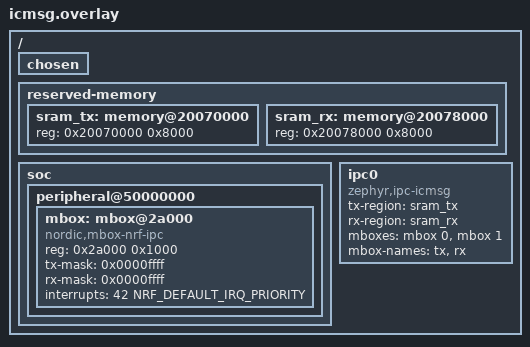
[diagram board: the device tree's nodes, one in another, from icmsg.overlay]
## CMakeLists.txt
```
#
# Copyright (c) 2024 Nordic Semiconductor ASA
#
# SPDX-License-Identifier: LicenseRef-Nordic-5-Clause
#

cmake_minimum_required(VERSION 3.20.0)

find_package(Zephyr REQUIRED HINTS $ENV{ZEPHYR_BASE})
project(ipc_service_host)

target_sources(app PRIVATE src/main.c)
if(CONFIG_SOC_NRF54H20_IRON)
  target_sources(app PRIVATE periphconf_migrated_src/periphconf_migrated_from_uicr.c)
endif()
```

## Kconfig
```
#
# Copyright (c) 2022 Nordic Semiconductor ASA
#
# SPDX-License-Identifier: LicenseRef-Nordic-5-Clause
#

source "Kconfig.zephyr"
rsource "Kconfig.common"
```

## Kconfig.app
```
#
# Copyright (c) 2022 Nordic Semiconductor ASA
#
# SPDX-License-Identifier: LicenseRef-Nordic-5-Clause
#

config APP_IPC_SERVICE_SEND_INTERVAL
	int "Ipc service sending interval [us]"
	default 30 if BOARD_NRF5340DK_NRF5340_CPUNET
	default 70
	help
	  Time in micro seconds between sending subsequent data packages over
	  IPC service. Since kernel timeout has 1 ms resolution, the value is
	  rounded down. If value of this option is lower than 1000 us, busy
	  wait is used instead of sleep.

config APP_IPC_SERVICE_MESSAGE_LEN
	int "Length of single IPC message in bytes"
	default 100
```

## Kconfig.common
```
#
# Copyright (c) 2024 Nordic Semiconductor ASA
#
# SPDX-License-Identifier: LicenseRef-Nordic-5-Clause
#

config APP_IPC_SERVICE_SEND_INTERVAL
	int "Ipc service sending interval [us]"
	default 30 if BOARD_NRF5340DK_NRF5340_CPUNET || BOARD_NRF7002DK_NRF5340_CPUNET
	default 70
	help
	  Time in micro seconds between sending subsequent data packages over
	  IPC service. Since kernel timeout has 1 ms resolution, the value is
	  rounded down. If value of this option is lower than 1000 us, busy
	  wait is used instead of sleep.

config APP_IPC_SERVICE_MESSAGE_LEN
	int "Length of single IPC message in bytes"
	default 100
```

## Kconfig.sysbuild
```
#
# Copyright (c) 2024 Nordic Semiconductor ASA
#
# SPDX-License-Identifier: LicenseRef-Nordic-5-Clause
#

if SUPPORT_PPRCORE

choice PPRCORE
	default PPRCORE_REMOTE if SOC_SERIES_NRF92
	default PPRCORE_NONE

config PPRCORE_REMOTE
	bool "remote image"

endchoice

config PPRCORE_IMAGE_NAME
	default "remote" if PPRCORE_REMOTE

config PPRCORE_IMAGE_PATH
	default "$(APP_DIR)/remote" if PPRCORE_REMOTE

endif # SUPPORT_PPRCORE

if SUPPORT_NETCORE

choice NETCORE
	default NETCORE_REMOTE

config NETCORE_REMOTE
	bool "remote image"

endchoice

config NETCORE_IMAGE_NAME
	default "remote" if NETCORE_REMOTE

config NETCORE_IMAGE_PATH
	default "$(APP_DIR)/remote" if NETCORE_REMOTE

endif # SUPPORT_NETCORE

if SUPPORT_FLPRCORE && !SOC_SERIES_NRF92 && !SUPPORT_PPRCORE

choice FLPRCORE
	default FLPRCORE_REMOTE

config FLPRCORE_REMOTE
	bool "remote image"

endchoice

config FLPRCORE_IMAGE_NAME
	default "remote" if FLPRCORE_REMOTE

config FLPRCORE_IMAGE_PATH
	default "$(APP_DIR)/remote" if FLPRCORE_REMOTE

endif # SUPPORT_FLPRCORE && !SOC_SERIES_NRF92 && !SUPPORT_PPRCORE

source "share/sysbuild/Kconfig"
```

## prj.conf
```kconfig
# Copyright (c) 2024 Nordic Semiconductor ASA
# SPDX-License-Identifier: LicenseRef-Nordic-5-Clause

CONFIG_PRINTK=y

CONFIG_LOG=y
CONFIG_LOG_PROCESS_THREAD_PRIORITY=-15
CONFIG_LOG_PROCESS_THREAD_CUSTOM_PRIORITY=y

CONFIG_HEAP_MEM_POOL_SIZE=4096

CONFIG_MBOX=y

CONFIG_IPC_SERVICE=y
CONFIG_IPC_SERVICE_LOG_LEVEL_INF=y
```

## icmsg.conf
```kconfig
CONFIG_APP_IPC_SERVICE_SEND_INTERVAL=60
```

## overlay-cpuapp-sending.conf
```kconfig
# Simulate sending from App core only, by decreasing
# App core sending interval to relatively low value.
CONFIG_APP_IPC_SERVICE_SEND_INTERVAL=1
```

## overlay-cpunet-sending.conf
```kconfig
# Simulate sending from Net core only, by increasing
# App core sending interval to relatively high value.
CONFIG_APP_IPC_SERVICE_SEND_INTERVAL=20000000
```

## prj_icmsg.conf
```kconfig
CONFIG_IPC_SERVICE=y

CONFIG_PRINTK=y
CONFIG_LOG=y

CONFIG_APP_IPC_SERVICE_SEND_INTERVAL=60

CONFIG_HEAP_MEM_POOL_SIZE=4096

CONFIG_IPC_SERVICE_LOG_LEVEL_INF=y
CONFIG_IPC_SERVICE_BACKEND_ICMSG=y
CONFIG_MBOX=y

CONFIG_LOG_PROCESS_THREAD_PRIORITY=-15
CONFIG_LOG_PROCESS_THREAD_CUSTOM_PRIORITY=y
```

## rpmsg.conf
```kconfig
CONFIG_OPENAMP=y
CONFIG_OPENAMP_SLAVE=n
```

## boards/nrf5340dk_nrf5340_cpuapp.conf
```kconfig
#
# Copyright (c) 2022 Nordic Semiconductor ASA
#
# SPDX-License-Identifier: LicenseRef-Nordic-5-Clause
#

CONFIG_BOARD_ENABLE_CPUNET=y
CONFIG_OPENAMP=y
CONFIG_OPENAMP_SLAVE=n
```

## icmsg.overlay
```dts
/*
* Copyright (c) 2022 Nordic Semiconductor ASA
*
* SPDX-License-Identifier: Apache-2.0
*/

/delete-node/ &ipc0;

/ {
	chosen {
		/delete-property/ zephyr,ipc_shm;
	};

	reserved-memory {
		/delete-node/ memory@20070000;

		sram_tx: memory@20070000 {
			reg = <0x20070000 0x8000>;
		};

		sram_rx: memory@20078000 {
			reg = <0x20078000 0x8000>;
		};
	};

	soc {
		peripheral@50000000 {
			/delete-node/ ipc@2a000;

			mbox: mbox@2a000 {
				compatible = "nordic,mbox-nrf-ipc";
				reg = <0x2a000 0x1000>;
				tx-mask = <0x0000ffff>;
				rx-mask = <0x0000ffff>;
				interrupts = <42 NRF_DEFAULT_IRQ_PRIORITY>;
				#mbox-cells = <1>;
				status = "okay";
			};
		};
	};

	ipc0: ipc0 {
		compatible = "zephyr,ipc-icmsg";
		tx-region = <&sram_tx>;
		rx-region = <&sram_rx>;
		mboxes = <&mbox 0>, <&mbox 1>;
		mbox-names = "tx", "rx";
		status = "okay";
	};
};
```

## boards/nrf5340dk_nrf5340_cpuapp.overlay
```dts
/*
 * Copyright (c) 2026 Nordic Semiconductor ASA
 *
 * SPDX-License-Identifier: Apache-2.0
 */

#include <zephyr/dt-bindings/ipc_service/static_vrings.h>

/delete-node/ &ipc0;

/ {
	chosen {
		/delete-property/ zephyr,ipc_shm;
		/delete-property/ zephyr,bt-hci;
	};
};

/ {
	reserved-memory {
		#address-cells = <1>;
		#size-cells = <1>;

		sram_ipc0: memory@20070000 {
			reg = <0x20070000 DT_SIZE_K(64)>;
		};
	};

	ipc0: ipc0 {
		compatible = "zephyr,ipc-openamp-static-vrings";
		memory-region = <&sram_ipc0>;
		mboxes = <&mbox 0>, <&mbox 1>;
		mbox-names = "tx", "rx";
		role = "host";
		zephyr,buffer-size = <128>;
		status = "okay";
	};
};
```

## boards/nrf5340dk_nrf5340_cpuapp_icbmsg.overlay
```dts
/*
 * Copyright (c) 2025 Nordic Semiconductor ASA
 *
 * SPDX-License-Identifier: LicenseRef-Nordic-5-Clause
 */

/delete-node/ &ipc0;
/delete-node/ &sram0_shared;

/ {
	chosen {
		/delete-property/ zephyr,ipc_shm;
		/delete-property/ zephyr,bt-hci;
	};

	reserved-memory {
		#address-cells = <1>;
		#size-cells = <1>;
		ranges;

		sram_tx: memory@20070000 {
			reg = <0x20070000 0x8000>;
		};

		sram_rx: memory@20078000 {
			reg = <0x20078000 0x8000>;
		};
	};

	ipc0: ipc0 {
		compatible = "zephyr,ipc-icbmsg";
		tx-region = <&sram_tx>;
		rx-region = <&sram_rx>;
		tx-blocks = <20>;
		rx-blocks = <20>;
		mboxes = <&mbox 0>, <&mbox 1>;
		mbox-names = "tx", "rx";
		status = "okay";
	};
};
```

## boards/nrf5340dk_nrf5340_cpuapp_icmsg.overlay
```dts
/*
 * Copyright (c) 2022 Nordic Semiconductor ASA
 *
 * SPDX-License-Identifier: LicenseRef-Nordic-5-Clause
 */

/delete-node/ &ipc0;
/delete-node/ &sram0_shared;

/ {
	chosen {
		/delete-property/ zephyr,ipc_shm;
		/delete-property/ zephyr,bt-hci;
	};

	reserved-memory {
		#address-cells = <1>;
		#size-cells = <1>;
		ranges;

		sram_tx: memory@20070000 {
			reg = <0x20070000 0x8000>;
		};

		sram_rx: memory@20078000 {
			reg = <0x20078000 0x8000>;
		};
	};

	ipc0: ipc0 {
		compatible = "zephyr,ipc-icmsg";
		tx-region = <&sram_tx>;
		rx-region = <&sram_rx>;
		mboxes = <&mbox 0>, <&mbox 1>;
		mbox-names = "tx", "rx";
		status = "okay";
	};
};
```

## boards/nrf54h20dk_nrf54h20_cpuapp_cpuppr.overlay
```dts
/*
 * Copyright (c) 2024 Nordic Semiconductor ASA
 * SPDX-License-Identifier: LicenseRef-Nordic-5-Clause
 */

/* Replace default ipc0 instance */
/delete-node/ &ipc0;

ipc0: &cpuapp_cpuppr_ipc {
	status = "okay";
};

/ {
	chosen {
		/delete-property/ zephyr,bt-hci;
	};
};
```

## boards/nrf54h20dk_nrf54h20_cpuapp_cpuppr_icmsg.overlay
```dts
/*
 * Copyright (c) 2026 Nordic Semiconductor ASA
 * SPDX-License-Identifier: LicenseRef-Nordic-5-Clause
 */

/* Replace default ipc0 instance */
/delete-node/ &ipc0;

ipc0: &cpuapp_cpuppr_ipc {
	compatible = "zephyr,ipc-icmsg";
	/delete-property/ tx-blocks;
	/delete-property/ rx-blocks;

};

/ {
	chosen {
		/delete-property/ zephyr,bt-hci;
	};
};
```

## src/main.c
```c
/*
 * Copyright (c) 2022 Nordic Semiconductor ASA
 *
 * SPDX-License-Identifier: LicenseRef-Nordic-5-Clause
 */

#include <zephyr/kernel.h>
#include <zephyr/device.h>
#include <string.h>

#include <zephyr/logging/log.h>

#include <zephyr/ipc/ipc_service.h>

#ifdef CONFIG_TEST_EXTRA_STACK_SIZE
#define STACKSIZE	(1024 + CONFIG_TEST_EXTRA_STACK_SIZE)
#else
#define STACKSIZE	(1024)
#endif

K_THREAD_STACK_DEFINE(ipc0_stack, STACKSIZE);

LOG_MODULE_REGISTER(host, LOG_LEVEL_INF);

struct payload {
	unsigned long cnt;
	unsigned long size;
	uint8_t data[];
};

struct payload *p_payload;

static K_SEM_DEFINE(bound_sem, 0, 1);

static void ep_bound(void *priv)
{
	k_sem_give(&bound_sem);
}

static void ep_recv(const void *data, size_t len, void *priv)
{
	uint8_t received_val = *((uint8_t *)data);
	static uint8_t expected_val;


	if ((received_val != expected_val) || (len != CONFIG_APP_IPC_SERVICE_MESSAGE_LEN)) {
		printk("Unexpected message received_val: %d , expected_val: %d\n",
			received_val,
			expected_val);
	}

	expected_val++;
}

static struct ipc_ept_cfg ep_cfg = {
	.name = "ep0",
	.cb = {
		.bound    = ep_bound,
		.received = ep_recv,
	},
};

static void check_task(void *arg1, void *arg2, void *arg3)
{
	ARG_UNUSED(arg1);
	ARG_UNUSED(arg2);
	ARG_UNUSED(arg3);

	unsigned long last_cnt = p_payload->cnt;
	unsigned long delta;

	while (1) {
		k_sleep(K_MSEC(1000));

		delta = p_payload->cnt - last_cnt;

		printk("Δpkt: %ld (%ld B/pkt) | throughput: %ld bit/s\n",
			delta, p_payload->size, delta * CONFIG_APP_IPC_SERVICE_MESSAGE_LEN * 8);

		last_cnt = p_payload->cnt;
	}
}

K_THREAD_DEFINE(thread_check_id, STACKSIZE, check_task, NULL, NULL, NULL,
		K_PRIO_COOP(1), 0, -1);

int main(void)
{
	const struct device *ipc0_instance;
	struct ipc_ept ep;
	int ret;

	p_payload = (struct payload *) k_malloc(CONFIG_APP_IPC_SERVICE_MESSAGE_LEN);
	if (!p_payload) {
		printk("k_malloc() failure\n");
		return -ENOMEM;
	}

	memset(p_payload->data, 0xA5, CONFIG_APP_IPC_SERVICE_MESSAGE_LEN - sizeof(struct payload));

	p_payload->size = CONFIG_APP_IPC_SERVICE_MESSAGE_LEN;
	p_payload->cnt = 0;

	printk("IPC-service %s demo started\n", CONFIG_BOARD_TARGET);

	ipc0_instance = DEVICE_DT_GET(DT_NODELABEL(ipc0));

#if defined(CONFIG_IPC_SERVICE_BACKEND_ICBMSG)
	/* Wait a bit for the remote core to boot. */
	k_msleep(100);
#endif

	ret = ipc_service_open_instance(ipc0_instance);
	if ((ret < 0) && (ret != -EALREADY)) {
		LOG_INF("ipc_service_open_instance() failure (%d)", ret);
		return ret;
	}

	ret = ipc_service_register_endpoint(ipc0_instance, &ep, &ep_cfg);
	if (ret < 0) {
		printf("ipc_service_register_endpoint() failure (%d)", ret);
		return ret;
	}

	k_sem_take(&bound_sem, K_FOREVER);
	k_thread_start(thread_check_id);

	while (true) {
		ret = ipc_service_send(&ep, p_payload, CONFIG_APP_IPC_SERVICE_MESSAGE_LEN);
		if (ret == -ENOMEM) {
			/* No space in the buffer. Retry. */
			continue;
		} else if (ret < 0) {
			printk("send_message(%ld) failed with ret %d\n", p_payload->cnt, ret);
			break;
		}

		p_payload->cnt++;


		/* Quasi minimal busy wait time which allows to continuously send
		 * data without -ENOMEM error code. The purpose is to test max
		 * throughput. Determined experimentally.
		 */
		if (CONFIG_APP_IPC_SERVICE_SEND_INTERVAL < 1000) {
			k_busy_wait(CONFIG_APP_IPC_SERVICE_SEND_INTERVAL);
		} else {
			k_msleep(CONFIG_APP_IPC_SERVICE_SEND_INTERVAL/1000);
		}
	}

	return 0;
}
```
